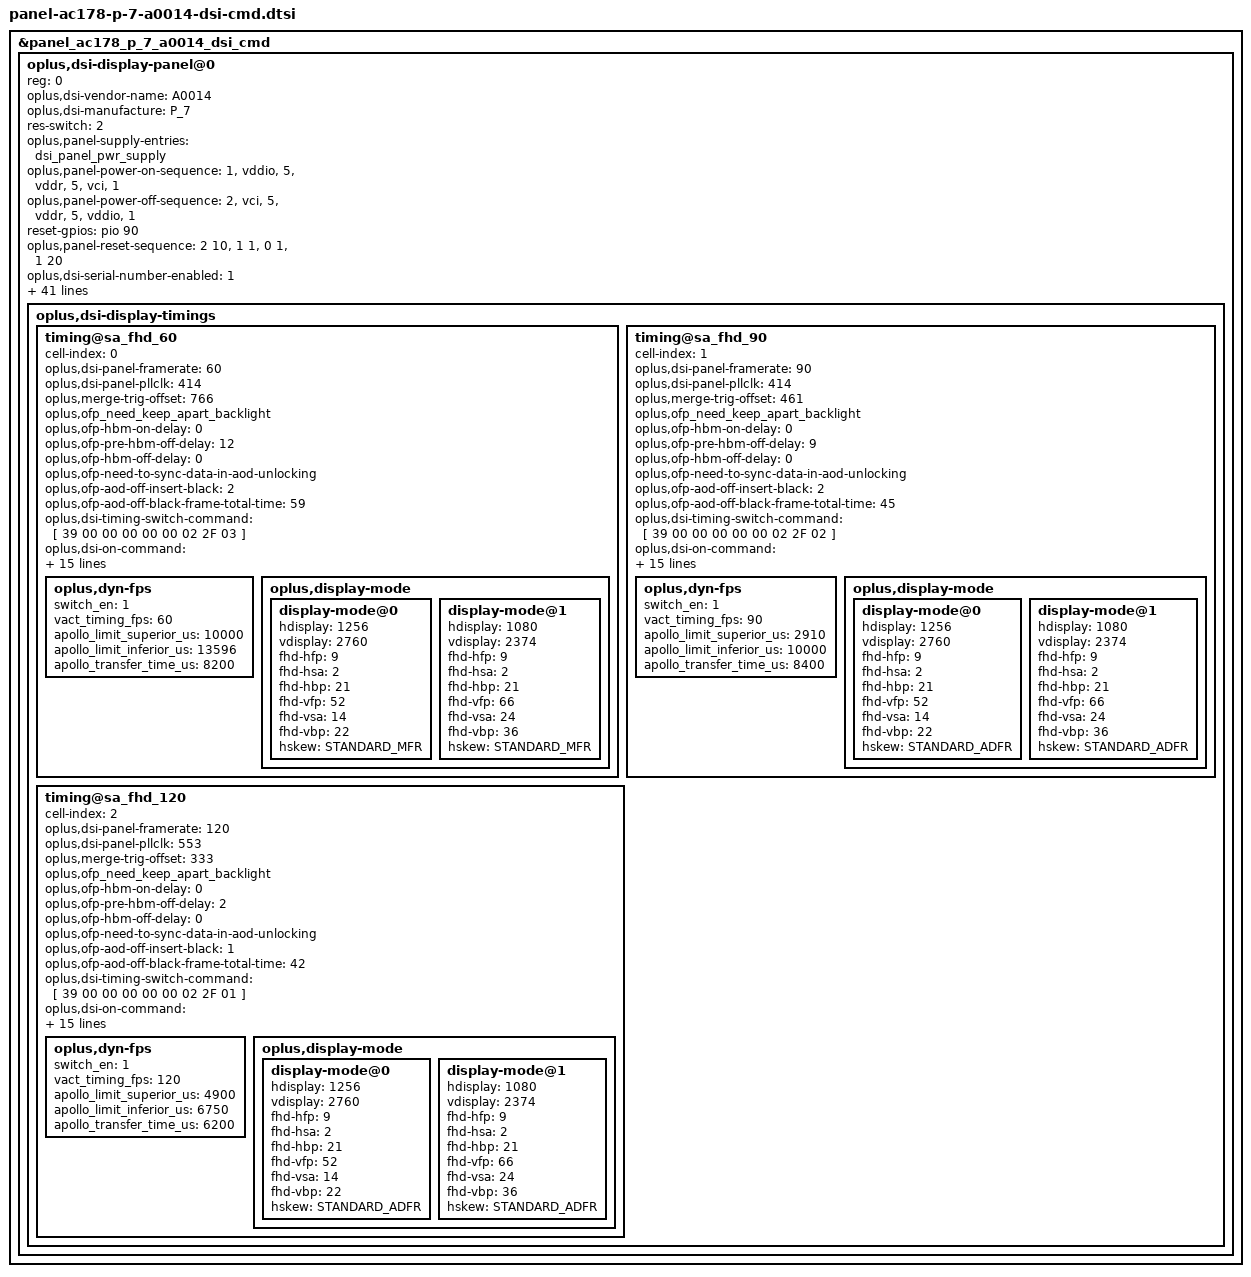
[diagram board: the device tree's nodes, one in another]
&panel_ac178_p_7_a0014_dsi_cmd {
	oplus,dsi-display-panel@0 {
		reg = <0>;
		oplus,dsi-vendor-name = "A0014";
		oplus,dsi-manufacture = "P_7";
		/* round corner */
		#include "panel-ac178-p-7-a0014-dsi-cmd-round-corner.dtsi"
		oplus,dsi-display-timings {
			timing@sa_fhd_60 {
				cell-index = <0>;
				oplus,dsi-panel-framerate = <60>;
				oplus,dsi-panel-pllclk = <414>;
				oplus,merge-trig-offset = <766>;
				/* OPLUS_FEATURE_DISPLAY_ONSCREENFINGERPRINT */
				oplus,ofp_need_keep_apart_backlight;
				oplus,ofp-hbm-on-delay = <0>;
				oplus,ofp-pre-hbm-off-delay = <12>;
				oplus,ofp-hbm-off-delay = <0>;
				oplus,ofp-need-to-sync-data-in-aod-unlocking;
				oplus,ofp-aod-off-insert-black = <2>;
				oplus,ofp-aod-off-black-frame-total-time = <59>;
				#include "panel-ac178-p-7-a0014-dsi-cmd-common.dtsi"
				oplus,dsi-timing-switch-command = [
					39 00 00 00 00 00 02 2F 03
				];
				oplus,dsi-on-command = [
					39 00 00 00 00 00 05 FF AA 55 A5 80
					39 00 00 00 00 00 02 6F 31
					39 00 00 00 00 00 03 F8 01 BD
					39 00 00 00 00 00 05 FF AA 55 A5 80
					39 00 00 00 00 00 02 6F 15
					39 00 00 00 00 00 03 F8 01 8C
					39 00 00 00 00 00 02 5A 01
					39 00 00 00 00 00 06 F0 55 AA 52 08 07
					39 00 00 00 00 00 02 C1 00
					39 00 00 00 00 00 02 C2 00
					39 00 00 00 00 00 02 C3 00
					39 00 00 00 00 00 02 C4 00
					39 00 00 00 00 00 02 C5 00
					39 00 00 00 00 00 02 C6 00
					39 00 00 00 00 00 02 D1 00
					39 00 00 00 00 00 05 FF AA 55 A5 80
					39 00 00 00 00 00 02 6F 0A
					39 00 00 00 00 00 06 F6 70 70 70 70 70
					39 00 00 00 00 00 05 FF AA 55 A5 81
					39 00 00 00 00 00 02 6F 0D
					39 00 00 00 00 00 02 FB 80
					39 00 00 00 00 00 06 F0 55 AA 52 08 01
					39 00 00 00 00 00 02 E5 00
					39 00 00 00 00 00 05 FF AA 55 A5 81
					39 00 00 00 00 00 02 6F 0C
					39 00 00 00 00 00 02 FD 08
					39 00 00 00 00 00 02 6F 02
					39 00 00 00 00 00 02 F9 84
					39 00 00 00 00 00 02 6F 10
					39 00 00 00 00 00 02 FB 40
					39 00 00 00 00 00 02 6F 0B
					39 00 00 00 00 00 02 FD 00
					39 00 00 00 00 00 05 FF AA 55 A5 80
					39 00 00 00 00 00 02 6F 48
					39 00 00 00 00 00 02 F2 00
					39 00 00 00 00 00 02 6F 16
					39 00 00 00 00 00 03 F4 02 74
					39 00 00 00 00 00 02 6F 42
					39 00 00 00 00 00 02 F4 00
					39 00 00 00 00 00 02 6F 49
					39 00 00 00 00 00 02 F2 10
					39 00 00 00 00 00 05 FF AA 55 A5 81
					39 00 00 00 00 00 02 6F 05
					39 00 00 00 00 00 03 FE 3C 3C
					39 00 00 00 00 00 05 FF AA 55 A5 82
					39 00 00 00 00 00 02 6F 09
					39 00 00 00 00 00 02 F2 FF
					39 00 00 00 00 00 05 FF AA 55 A5 80
					39 00 00 00 00 00 02 6F 04
					39 00 00 00 00 00 02 F2 3C
					39 00 00 00 00 00 02 17 30
					39 00 00 00 00 00 02 2F 03
					39 00 00 00 00 00 03 5F 00 00
					39 00 00 00 00 00 02 35 00
					39 00 00 00 00 00 02 53 20
					39 00 00 00 00 00 05 2A 00 00 04 E7
					39 00 00 00 00 00 05 2B 00 00 0A C7
					39 00 00 00 00 00 06 F0 55 AA 52 08 02
					39 00 00 00 00 00 02 C1 02
					39 00 00 00 00 00 05 C2 19 00 91 00
					39 00 00 00 00 00 06 F0 55 AA 52 08 03
					39 00 00 00 00 00 02 6F 08
					39 00 00 00 00 00 02 DE 00
					39 00 00 00 00 00 02 6F 09
					39 00 00 00 00 00 07 DE 10 34 25 30 14 25
					39 00 00 00 00 00 06 F0 55 AA 52 08 07
					39 00 00 00 00 00 02 B0 44
					39 00 00 00 00 00 07 B1 60 60 00 60 60 00
					39 00 00 00 00 00 03 90 03 43
					39 00 00 00 00 00 02 03 00
					39 00 00 00 00 00 13 91 A0 F0 00 0C D1 00 01 D2 00 57 00 34 09 75 29 25 11 50
					39 00 00 00 00 00 13 93 AB A8 00 0C C2 00 02 3B 01 35 00 08 08 BB 07 44 10 F0
					39 00 00 00 00 00 02 26 00
					39 00 00 00 00 00 06 F0 55 AA 52 08 01
					39 00 00 00 00 00 02 DD 4F
					39 00 00 00 00 00 03 81 01 19
					39 00 00 00 00 00 06 F0 55 AA 52 08 00
					39 00 00 00 00 00 02 6F 03
					39 00 00 00 00 00 02 B5 65
					39 00 00 00 00 00 02 6F 08
					39 00 00 00 00 00 02 D5 04
					39 00 00 00 00 00 02 6F 19
					39 00 00 00 00 00 02 D5 0E // DVDD 1.05V
					39 00 00 00 00 00 02 6F 4D
					39 00 00 00 00 00 02 D5 01
					39 00 00 00 00 00 06 F0 55 AA 52 08 01
					39 00 00 00 00 00 02 CE 00
					39 00 00 00 00 00 06 F0 55 AA 52 08 01
					39 00 00 00 00 00 02 6F 0E
					39 00 00 00 00 00 02 D2 00
					39 00 00 00 00 00 02 6F 03
					39 00 00 00 00 00 04 C5 00 23 23 // DVDD STRONG 1.01
					39 00 00 00 00 00 06 F0 55 AA 52 08 00
					39 00 00 00 00 00 02 C0 56
					39 00 00 00 00 00 0A 88 01 02 74 09 B4 00 00 00 00
					39 00 00 00 00 00 06 F0 55 AA 52 08 00
					39 00 00 00 00 00 02 6F 13
					39 00 00 00 00 00 19 DF 00 64 00 64 00 00 00 00 00 00 00 00 00 C7 00 C7 00 00 00 00 00 00 00 00
					39 00 00 00 00 00 06 F0 55 AA 52 08 07
					39 00 00 00 00 00 16 C9 21 00 26 49 26 49 00 00 3F E2 63 8A 3F E2 63 8A 00 05 B9 C0 D1
					39 00 00 00 00 00 02 6F 15
					39 00 00 00 00 00 11 C9 1C 00 00 63 00 00 63 33 F0 9D 9D 26 49 00 00 00
					39 00 00 00 00 00 16 CA 2D 00 26 49 26 49 00 00 3F E2 63 8A 00 00 00 00 00 00 00 00 00
					39 00 00 00 00 00 02 6F 15
					39 00 00 00 00 00 11 CA 46 00 00 63 00 64 C7 33 C0 9D 63 00 00 00 00 00
					39 00 00 00 00 00 16 CB 2B 00 26 49 26 49 00 00 00 00 00 00 00 00 00 00 7F FA 46 3F 2F
					39 00 00 00 00 00 02 6F 15
					39 00 00 00 00 00 11 CB 46 00 64 C7 00 64 C7 33 0F 63 63 D9 B7 00 00 00
					39 00 00 00 00 00 16 CC 27 00 26 49 26 49 00 00 00 00 00 00 3F E2 63 8A 00 00 00 00 00
					39 00 00 00 00 00 02 6F 15
					39 00 00 00 00 00 11 CC 1C 00 64 C7 00 00 63 33 30 63 9D 00 00 00 00 00
					39 00 00 00 00 00 06 F0 55 AA 52 08 00
					39 00 00 00 00 00 03 DF 01 44
					39 00 00 00 00 00 06 F0 55 AA 52 08 08
					39 00 00 00 00 00 02 6F 30
					39 00 00 00 00 00 15 B2 00 00 3B 45 21 C4 25 E4 2A C4 2F 64 3A 44 24 C3 30 C3 3A 93
					39 00 00 00 00 00 02 6F 44
					39 00 00 00 00 00 15 B2 24 02 2B C2 35 52 1F 71 24 D1 2A E1 31 81 35 81 20 90 24 C0
					39 00 00 00 00 00 02 6F 58
					39 00 00 00 00 00 0B B2 29 00 2D 50 00 1F 00 1F 00 1F
					39 00 00 00 00 00 06 F0 55 AA 52 08 00
					39 00 00 00 00 00 02 C3 04
					39 00 00 00 00 00 06 F0 55 AA 52 08 08
					39 00 00 00 00 00 07 B0 11 05 39 1D 20 20
					39 00 00 00 00 00 02 6F 07
					39 00 00 00 00 00 08 B0 21 D3 6C 32 ED 6E F3
					39 00 00 00 00 00 02 6F 0E
					39 00 00 00 00 00 08 B0 FF FF 31 DE BC E3 BC
					39 00 00 00 00 00 02 6F 15
					39 00 00 00 00 00 08 B0 E1 FF FF FF 05 AD 16
					39 00 00 00 00 00 02 6F 1C
					39 00 00 00 00 00 05 B0 FE 8A 00 17
					39 00 00 00 78 00 01 11
					39 00 00 00 00 00 01 29
				];
				oplus,dsi-aod-off-command = [
					39 00 00 40 00 00 02 38 00
					39 00 00 00 00 00 03 51 00 00
				];
				oplus,dsi-hbm-on-command = [
					39 00 00 00 00 00 03 51 0E 7A
				];
				oplus,dsi-hbm-off-command = [
					39 00 00 00 00 00 03 51 0D BB
				];

				oplus,dsi-timing-switch-command-state = "dsi_hs_mode";
				oplus,dsi-on-command-state = "dsi_lp_mode";
				oplus,dsi-aod-off-command-state = "dsi_ls_mode";
				oplus,dsi-hbm-on-command-state = "dsi_hs_mode";
				oplus,dsi-hbm-off-command-state = "dsi_hs_mode";
				oplus,dsc-params-entries = <&dsc_params>;
				oplus,spr-params-entries = <&spr_params>;
				oplus,dyn-fps {
					switch_en = <1>;
					vact_timing_fps = <60>;
					apollo_limit_superior_us = <10000>;
					apollo_limit_inferior_us = <13596>;
					apollo_transfer_time_us = <8200>;
				};
				oplus,display-mode {
					display-mode@0 {
						hdisplay = <1256>;
						vdisplay = <2760>;
						fhd-hfp = <9>;
						fhd-hsa = <2>;
						fhd-hbp = <21>;
						fhd-vfp = <52>;
						fhd-vsa = <14>;
						fhd-vbp = <22>;
						hskew = <STANDARD_MFR>;
					};
					display-mode@1 {
						hdisplay = <1080>;
						vdisplay = <2374>;
						fhd-hfp = <9>;
						fhd-hsa = <2>;
						fhd-hbp = <21>;
						fhd-vfp = <66>;
						fhd-vsa = <24>;
						fhd-vbp = <36>;
						hskew = <STANDARD_MFR>;
					};
				};
			};
			timing@sa_fhd_90 {
				cell-index = <1>;
				oplus,dsi-panel-framerate = <90>;
				oplus,dsi-panel-pllclk = <414>;
				oplus,merge-trig-offset = <461>;
				/* OPLUS_FEATURE_DISPLAY_ONSCREENFINGERPRINT */
				oplus,ofp_need_keep_apart_backlight;
				oplus,ofp-hbm-on-delay = <0>;
				oplus,ofp-pre-hbm-off-delay = <9>;
				oplus,ofp-hbm-off-delay = <0>;
				oplus,ofp-need-to-sync-data-in-aod-unlocking;
				oplus,ofp-aod-off-insert-black = <2>;
				oplus,ofp-aod-off-black-frame-total-time = <45>;
				#include "panel-ac178-p-7-a0014-dsi-cmd-common.dtsi"
				oplus,dsi-timing-switch-command = [
					39 00 00 00 00 00 02 2F 02
				];
				oplus,dsi-on-command = [
					39 00 00 00 00 00 05 FF AA 55 A5 80
					39 00 00 00 00 00 02 6F 31
					39 00 00 00 00 00 03 F8 01 BD
					39 00 00 00 00 00 05 FF AA 55 A5 80
					39 00 00 00 00 00 02 6F 15
					39 00 00 00 00 00 03 F8 01 8C
					39 00 00 00 00 00 02 5A 01
					39 00 00 00 00 00 06 F0 55 AA 52 08 07
					39 00 00 00 00 00 02 C1 00
					39 00 00 00 00 00 02 C2 00
					39 00 00 00 00 00 02 C3 00
					39 00 00 00 00 00 02 C4 00
					39 00 00 00 00 00 02 C5 00
					39 00 00 00 00 00 02 C6 00
					39 00 00 00 00 00 02 D1 00
					39 00 00 00 00 00 05 FF AA 55 A5 80
					39 00 00 00 00 00 02 6F 0A
					39 00 00 00 00 00 06 F6 70 70 70 70 70
					39 00 00 00 00 00 05 FF AA 55 A5 81
					39 00 00 00 00 00 02 6F 0D
					39 00 00 00 00 00 02 FB 80
					39 00 00 00 00 00 06 F0 55 AA 52 08 01
					39 00 00 00 00 00 02 E5 00
					39 00 00 00 00 00 05 FF AA 55 A5 81
					39 00 00 00 00 00 02 6F 0C
					39 00 00 00 00 00 02 FD 08
					39 00 00 00 00 00 02 6F 02
					39 00 00 00 00 00 02 F9 84
					39 00 00 00 00 00 02 6F 10
					39 00 00 00 00 00 02 FB 40
					39 00 00 00 00 00 02 6F 0B
					39 00 00 00 00 00 02 FD 00
					39 00 00 00 00 00 05 FF AA 55 A5 80
					39 00 00 00 00 00 02 6F 48
					39 00 00 00 00 00 02 F2 00
					39 00 00 00 00 00 02 6F 16
					39 00 00 00 00 00 03 F4 02 74
					39 00 00 00 00 00 02 6F 42
					39 00 00 00 00 00 02 F4 00
					39 00 00 00 00 00 02 6F 49
					39 00 00 00 00 00 02 F2 10
					39 00 00 00 00 00 05 FF AA 55 A5 81
					39 00 00 00 00 00 02 6F 05
					39 00 00 00 00 00 03 FE 3C 3C
					39 00 00 00 00 00 05 FF AA 55 A5 82
					39 00 00 00 00 00 02 6F 09
					39 00 00 00 00 00 02 F2 FF
					39 00 00 00 00 00 05 FF AA 55 A5 80
					39 00 00 00 00 00 02 6F 04
					39 00 00 00 00 00 02 F2 3C
					39 00 00 00 00 00 02 17 30
					39 00 00 00 00 00 02 2F 02
					39 00 00 00 00 00 03 5F 00 00
					39 00 00 00 00 00 02 35 00
					39 00 00 00 00 00 02 53 20
					39 00 00 00 00 00 05 2A 00 00 04 E7
					39 00 00 00 00 00 05 2B 00 00 0A C7
					39 00 00 00 00 00 06 F0 55 AA 52 08 02
					39 00 00 00 00 00 02 C1 02
					39 00 00 00 00 00 05 C2 19 00 91 00
					39 00 00 00 00 00 06 F0 55 AA 52 08 03
					39 00 00 00 00 00 02 6F 08
					39 00 00 00 00 00 02 DE 00
					39 00 00 00 00 00 02 6F 09
					39 00 00 00 00 00 07 DE 10 34 25 30 14 25
					39 00 00 00 00 00 06 F0 55 AA 52 08 07
					39 00 00 00 00 00 02 B0 44
					39 00 00 00 00 00 07 B1 60 60 00 60 60 00
					39 00 00 00 00 00 03 90 03 43
					39 00 00 00 00 00 02 03 00
					39 00 00 00 00 00 13 91 A0 F0 00 0C D1 00 01 D2 00 57 00 34 09 75 29 25 11 50
					39 00 00 00 00 00 13 93 AB A8 00 0C C2 00 02 3B 01 35 00 08 08 BB 07 44 10 F0
					39 00 00 00 00 00 02 26 00
					39 00 00 00 00 00 06 F0 55 AA 52 08 01
					39 00 00 00 00 00 02 DD 4F
					39 00 00 00 00 00 03 81 01 19
					39 00 00 00 00 00 06 F0 55 AA 52 08 00
					39 00 00 00 00 00 02 6F 03
					39 00 00 00 00 00 02 B5 65
					39 00 00 00 00 00 02 6F 08
					39 00 00 00 00 00 02 D5 04
					39 00 00 00 00 00 02 6F 19
					39 00 00 00 00 00 02 D5 0E // DVDD 1.05V
					39 00 00 00 00 00 02 6F 4D
					39 00 00 00 00 00 02 D5 01
					39 00 00 00 00 00 06 F0 55 AA 52 08 01
					39 00 00 00 00 00 02 CE 00
					39 00 00 00 00 00 06 F0 55 AA 52 08 01
					39 00 00 00 00 00 02 6F 0E
					39 00 00 00 00 00 02 D2 00
					39 00 00 00 00 00 02 6F 03
					39 00 00 00 00 00 04 C5 00 23 23 // DVDD STRONG 1.01
					39 00 00 00 00 00 06 F0 55 AA 52 08 00
					39 00 00 00 00 00 02 C0 56
					39 00 00 00 00 00 0A 88 01 02 74 09 B4 00 00 00 00
					39 00 00 00 00 00 06 F0 55 AA 52 08 00
					39 00 00 00 00 00 02 6F 13
					39 00 00 00 00 00 19 DF 00 64 00 64 00 00 00 00 00 00 00 00 00 C7 00 C7 00 00 00 00 00 00 00 00
					39 00 00 00 00 00 06 F0 55 AA 52 08 07
					39 00 00 00 00 00 16 C9 21 00 26 49 26 49 00 00 3F E2 63 8A 3F E2 63 8A 00 05 B9 C0 D1
					39 00 00 00 00 00 02 6F 15
					39 00 00 00 00 00 11 C9 1C 00 00 63 00 00 63 33 F0 9D 9D 26 49 00 00 00
					39 00 00 00 00 00 16 CA 2D 00 26 49 26 49 00 00 3F E2 63 8A 00 00 00 00 00 00 00 00 00
					39 00 00 00 00 00 02 6F 15
					39 00 00 00 00 00 11 CA 46 00 00 63 00 64 C7 33 C0 9D 63 00 00 00 00 00
					39 00 00 00 00 00 16 CB 2B 00 26 49 26 49 00 00 00 00 00 00 00 00 00 00 7F FA 46 3F 2F
					39 00 00 00 00 00 02 6F 15
					39 00 00 00 00 00 11 CB 46 00 64 C7 00 64 C7 33 0F 63 63 D9 B7 00 00 00
					39 00 00 00 00 00 16 CC 27 00 26 49 26 49 00 00 00 00 00 00 3F E2 63 8A 00 00 00 00 00
					39 00 00 00 00 00 02 6F 15
					39 00 00 00 00 00 11 CC 1C 00 64 C7 00 00 63 33 30 63 9D 00 00 00 00 00
					39 00 00 00 00 00 06 F0 55 AA 52 08 00
					39 00 00 00 00 00 03 DF 01 44
					39 00 00 00 00 00 06 F0 55 AA 52 08 08
					39 00 00 00 00 00 02 6F 30
					39 00 00 00 00 00 15 B2 00 00 3B 45 21 C4 25 E4 2A C4 2F 64 3A 44 24 C3 30 C3 3A 93
					39 00 00 00 00 00 02 6F 44
					39 00 00 00 00 00 15 B2 24 02 2B C2 35 52 1F 71 24 D1 2A E1 31 81 35 81 20 90 24 C0
					39 00 00 00 00 00 02 6F 58
					39 00 00 00 00 00 0B B2 29 00 2D 50 00 1F 00 1F 00 1F
					39 00 00 00 00 00 06 F0 55 AA 52 08 00
					39 00 00 00 00 00 02 C3 04
					39 00 00 00 00 00 06 F0 55 AA 52 08 08
					39 00 00 00 00 00 07 B0 11 05 39 1D 20 20
					39 00 00 00 00 00 02 6F 07
					39 00 00 00 00 00 08 B0 21 D3 6C 32 ED 6E F3
					39 00 00 00 00 00 02 6F 0E
					39 00 00 00 00 00 08 B0 FF FF 31 DE BC E3 BC
					39 00 00 00 00 00 02 6F 15
					39 00 00 00 00 00 08 B0 E1 FF FF FF 05 AD 16
					39 00 00 00 00 00 02 6F 1C
					39 00 00 00 00 00 05 B0 FE 8A 00 17
					39 00 00 00 78 00 01 11
					39 00 00 00 00 00 01 29
				];
				oplus,dsi-aod-off-command = [
					39 00 00 40 00 00 02 38 00
					39 00 00 00 00 00 03 51 00 00
				];
				oplus,dsi-hbm-on-command = [
					39 00 00 00 00 00 03 51 0E 7A
				];
				oplus,dsi-hbm-off-command = [
					39 00 00 00 00 00 03 51 0D BB
				];

				oplus,dsi-timing-switch-command-state = "dsi_hs_mode";
				oplus,dsi-on-command-state = "dsi_lp_mode";
				oplus,dsi-aod-off-command-state = "dsi_ls_mode";
				oplus,dsi-hbm-on-command-state = "dsi_hs_mode";
				oplus,dsi-hbm-off-command-state = "dsi_hs_mode";
				oplus,dsc-params-entries = <&dsc_params>;
				oplus,spr-params-entries = <&spr_params>;
				oplus,dyn-fps {
					switch_en = <1>;
					vact_timing_fps = <90>;
					apollo_limit_superior_us = <2910>;
					apollo_limit_inferior_us = <10000>;
					apollo_transfer_time_us = <8400>;
				};
				oplus,display-mode {
					display-mode@0 {
						hdisplay = <1256>;
						vdisplay = <2760>;
						fhd-hfp = <9>;
						fhd-hsa = <2>;
						fhd-hbp = <21>;
						fhd-vfp = <52>;
						fhd-vsa = <14>;
						fhd-vbp = <22>;
						hskew = <STANDARD_ADFR>;
					};
					display-mode@1 {
						hdisplay = <1080>;
						vdisplay = <2374>;
						fhd-hfp = <9>;
						fhd-hsa = <2>;
						fhd-hbp = <21>;
						fhd-vfp = <66>;
						fhd-vsa = <24>;
						fhd-vbp = <36>;
						hskew = <STANDARD_ADFR>;
					};
				};
			};
			timing@sa_fhd_120 {
				cell-index = <2>;
				oplus,dsi-panel-framerate = <120>;
				oplus,dsi-panel-pllclk = <553>;
				oplus,merge-trig-offset = <333>;
				/* OPLUS_FEATURE_DISPLAY_ONSCREENFINGERPRINT */
				oplus,ofp_need_keep_apart_backlight;
				oplus,ofp-hbm-on-delay = <0>;
				oplus,ofp-pre-hbm-off-delay = <2>;
				oplus,ofp-hbm-off-delay = <0>;
				oplus,ofp-need-to-sync-data-in-aod-unlocking;
				oplus,ofp-aod-off-insert-black = <1>;
				oplus,ofp-aod-off-black-frame-total-time = <42>;
				#include "panel-ac178-p-7-a0014-dsi-cmd-common.dtsi"
				oplus,dsi-timing-switch-command = [
					39 00 00 00 00 00 02 2F 01
				];
				oplus,dsi-on-command = [
					39 00 00 00 00 00 05 FF AA 55 A5 80
					39 00 00 00 00 00 02 6F 31
					39 00 00 00 00 00 03 F8 01 BD
					39 00 00 00 00 00 05 FF AA 55 A5 80
					39 00 00 00 00 00 02 6F 15
					39 00 00 00 00 00 03 F8 01 8C
					39 00 00 00 00 00 02 5A 01
					39 00 00 00 00 00 06 F0 55 AA 52 08 07
					39 00 00 00 00 00 02 C1 00
					39 00 00 00 00 00 02 C2 00
					39 00 00 00 00 00 02 C3 00
					39 00 00 00 00 00 02 C4 00
					39 00 00 00 00 00 02 C5 00
					39 00 00 00 00 00 02 C6 00
					39 00 00 00 00 00 02 D1 00
					39 00 00 00 00 00 05 FF AA 55 A5 80
					39 00 00 00 00 00 02 6F 0A
					39 00 00 00 00 00 06 F6 70 70 70 70 70
					39 00 00 00 00 00 05 FF AA 55 A5 81
					39 00 00 00 00 00 02 6F 0D
					39 00 00 00 00 00 02 FB 80
					39 00 00 00 00 00 06 F0 55 AA 52 08 01
					39 00 00 00 00 00 02 E5 00
					39 00 00 00 00 00 05 FF AA 55 A5 81
					39 00 00 00 00 00 02 6F 0C
					39 00 00 00 00 00 02 FD 08
					39 00 00 00 00 00 02 6F 02
					39 00 00 00 00 00 02 F9 84
					39 00 00 00 00 00 02 6F 10
					39 00 00 00 00 00 02 FB 40
					39 00 00 00 00 00 02 6F 0B
					39 00 00 00 00 00 02 FD 00
					39 00 00 00 00 00 05 FF AA 55 A5 80
					39 00 00 00 00 00 02 6F 48
					39 00 00 00 00 00 02 F2 00
					39 00 00 00 00 00 02 6F 16
					39 00 00 00 00 00 03 F4 02 74
					39 00 00 00 00 00 02 6F 42
					39 00 00 00 00 00 02 F4 00
					39 00 00 00 00 00 02 6F 49
					39 00 00 00 00 00 02 F2 10
					39 00 00 00 00 00 05 FF AA 55 A5 81
					39 00 00 00 00 00 02 6F 05
					39 00 00 00 00 00 03 FE 3C 3C
					39 00 00 00 00 00 05 FF AA 55 A5 82
					39 00 00 00 00 00 02 6F 09
					39 00 00 00 00 00 02 F2 FF
					39 00 00 00 00 00 05 FF AA 55 A5 80
					39 00 00 00 00 00 02 6F 04
					39 00 00 00 00 00 02 F2 3C
					39 00 00 00 00 00 02 17 30
					39 00 00 00 00 00 02 2F 01
					39 00 00 00 00 00 03 5F 00 00
					39 00 00 00 00 00 02 35 00
					39 00 00 00 00 00 02 53 20
					39 00 00 00 00 00 05 2A 00 00 04 E7
					39 00 00 00 00 00 05 2B 00 00 0A C7
					39 00 00 00 00 00 06 F0 55 AA 52 08 02
					39 00 00 00 00 00 02 C1 02
					39 00 00 00 00 00 05 C2 19 00 91 00
					39 00 00 00 00 00 06 F0 55 AA 52 08 03
					39 00 00 00 00 00 02 6F 08
					39 00 00 00 00 00 02 DE 00
					39 00 00 00 00 00 02 6F 09
					39 00 00 00 00 00 07 DE 10 34 25 30 14 25
					39 00 00 00 00 00 06 F0 55 AA 52 08 07
					39 00 00 00 00 00 02 B0 44
					39 00 00 00 00 00 07 B1 60 60 00 60 60 00
					39 00 00 00 00 00 03 90 03 43
					39 00 00 00 00 00 02 03 00
					39 00 00 00 00 00 13 91 A0 F0 00 0C D1 00 01 D2 00 57 00 34 09 75 29 25 11 50
					39 00 00 00 00 00 13 93 AB A8 00 0C C2 00 02 3B 01 35 00 08 08 BB 07 44 10 F0
					39 00 00 00 00 00 02 26 00
					39 00 00 00 00 00 06 F0 55 AA 52 08 01
					39 00 00 00 00 00 02 DD 4F
					39 00 00 00 00 00 03 81 01 19
					39 00 00 00 00 00 06 F0 55 AA 52 08 00
					39 00 00 00 00 00 02 6F 03
					39 00 00 00 00 00 02 B5 65
					39 00 00 00 00 00 02 6F 08
					39 00 00 00 00 00 02 D5 04
					39 00 00 00 00 00 02 6F 19
					39 00 00 00 00 00 02 D5 0E // DVDD 1.05V
					39 00 00 00 00 00 02 6F 4D
					39 00 00 00 00 00 02 D5 01
					39 00 00 00 00 00 06 F0 55 AA 52 08 01
					39 00 00 00 00 00 02 CE 00
					39 00 00 00 00 00 06 F0 55 AA 52 08 01
					39 00 00 00 00 00 02 6F 0E
					39 00 00 00 00 00 02 D2 00
					39 00 00 00 00 00 02 6F 03
					39 00 00 00 00 00 04 C5 00 23 23 // DVDD STRONG 1.01
					39 00 00 00 00 00 06 F0 55 AA 52 08 00
					39 00 00 00 00 00 02 C0 56
					39 00 00 00 00 00 0A 88 01 02 74 09 B4 00 00 00 00
					39 00 00 00 00 00 06 F0 55 AA 52 08 00
					39 00 00 00 00 00 02 6F 13
					39 00 00 00 00 00 19 DF 00 64 00 64 00 00 00 00 00 00 00 00 00 C7 00 C7 00 00 00 00 00 00 00 00
					39 00 00 00 00 00 06 F0 55 AA 52 08 07
					39 00 00 00 00 00 16 C9 21 00 26 49 26 49 00 00 3F E2 63 8A 3F E2 63 8A 00 05 B9 C0 D1
					39 00 00 00 00 00 02 6F 15
					39 00 00 00 00 00 11 C9 1C 00 00 63 00 00 63 33 F0 9D 9D 26 49 00 00 00
					39 00 00 00 00 00 16 CA 2D 00 26 49 26 49 00 00 3F E2 63 8A 00 00 00 00 00 00 00 00 00
					39 00 00 00 00 00 02 6F 15
					39 00 00 00 00 00 11 CA 46 00 00 63 00 64 C7 33 C0 9D 63 00 00 00 00 00
					39 00 00 00 00 00 16 CB 2B 00 26 49 26 49 00 00 00 00 00 00 00 00 00 00 7F FA 46 3F 2F
					39 00 00 00 00 00 02 6F 15
					39 00 00 00 00 00 11 CB 46 00 64 C7 00 64 C7 33 0F 63 63 D9 B7 00 00 00
					39 00 00 00 00 00 16 CC 27 00 26 49 26 49 00 00 00 00 00 00 3F E2 63 8A 00 00 00 00 00
					39 00 00 00 00 00 02 6F 15
					39 00 00 00 00 00 11 CC 1C 00 64 C7 00 00 63 33 30 63 9D 00 00 00 00 00
					39 00 00 00 00 00 06 F0 55 AA 52 08 00
					39 00 00 00 00 00 03 DF 01 44
					39 00 00 00 00 00 06 F0 55 AA 52 08 08
					39 00 00 00 00 00 02 6F 30
					39 00 00 00 00 00 15 B2 00 00 3B 45 21 C4 25 E4 2A C4 2F 64 3A 44 24 C3 30 C3 3A 93
					39 00 00 00 00 00 02 6F 44
					39 00 00 00 00 00 15 B2 24 02 2B C2 35 52 1F 71 24 D1 2A E1 31 81 35 81 20 90 24 C0
					39 00 00 00 00 00 02 6F 58
					39 00 00 00 00 00 0B B2 29 00 2D 50 00 1F 00 1F 00 1F
					39 00 00 00 00 00 06 F0 55 AA 52 08 00
					39 00 00 00 00 00 02 C3 04
					39 00 00 00 00 00 06 F0 55 AA 52 08 08
					39 00 00 00 00 00 07 B0 11 05 39 1D 20 20
					39 00 00 00 00 00 02 6F 07
					39 00 00 00 00 00 08 B0 21 D3 6C 32 ED 6E F3
					39 00 00 00 00 00 02 6F 0E
					39 00 00 00 00 00 08 B0 FF FF 31 DE BC E3 BC
					39 00 00 00 00 00 02 6F 15
					39 00 00 00 00 00 08 B0 E1 FF FF FF 05 AD 16
					39 00 00 00 00 00 02 6F 1C
					39 00 00 00 00 00 05 B0 FE 8A 00 17
					39 00 00 00 78 00 01 11
					39 00 00 00 00 00 01 29
				];
				oplus,dsi-aod-off-command = [
					39 00 00 40 00 00 02 38 00
					39 00 00 00 00 00 03 51 00 00
				];
				oplus,dsi-hbm-on-command = [
					39 00 00 00 00 00 03 51 0E 7A
				];
				oplus,dsi-hbm-off-command = [
					39 00 00 00 00 00 03 51 0D BB
				];

				oplus,dsi-timing-switch-command-state = "dsi_hs_mode";
				oplus,dsi-on-command-state = "dsi_lp_mode";
				oplus,dsi-aod-off-command-state = "dsi_ls_mode";
				oplus,dsi-hbm-on-command-state = "dsi_hs_mode";
				oplus,dsi-hbm-off-command-state = "dsi_hs_mode";
				oplus,dsc-params-entries = <&dsc_params>;
				oplus,spr-params-entries = <&spr_params>;
				oplus,dyn-fps {
					switch_en = <1>;
					vact_timing_fps = <120>;
					apollo_limit_superior_us = <4900>;
					apollo_limit_inferior_us = <6750>;
					apollo_transfer_time_us = <6200>;
				};
				oplus,display-mode {
					display-mode@0 {
						hdisplay = <1256>;
						vdisplay = <2760>;
						fhd-hfp = <9>;
						fhd-hsa = <2>;
						fhd-hbp = <21>;
						fhd-vfp = <52>;
						fhd-vsa = <14>;
						fhd-vbp = <22>;
						hskew = <STANDARD_ADFR>;
					};
					display-mode@1 {
						hdisplay = <1080>;
						vdisplay = <2374>;
						fhd-hfp = <9>;
						fhd-hsa = <2>;
						fhd-hbp = <21>;
						fhd-vfp = <66>;
						fhd-vsa = <24>;
						fhd-vbp = <36>;
						hskew = <STANDARD_ADFR>;
					};
				};
			};
		};
	};
};

&panel_ac178_p_7_a0014_dsi_cmd {
	oplus,dsi-display-panel@0 {
		res-switch = <2>;
		/* Hardware config */
		oplus,panel-supply-entries = <&dsi_panel_pwr_supply>;
		oplus,panel-power-on-sequence = "1", "vddio", "5", "vddr", "5", "vci", "1";
		oplus,panel-power-off-sequence = "2", "vci", "5", "vddr", "5", "vddio", "1";
		reset-gpios = <&pio 90 0>;
		oplus,panel-reset-sequence = <2 10>, <1 1>, <0 1>, <1 20>;
		/* Panel config */
		oplus,dsi-serial-number-enabled = <1>;
		oplus,dsi-serial-number-index = <0>;
		oplus,dsi-serial-number-reg = <0xA3>;
		oplus,dsi-serial-number-read-count = <6>;
		oplus,dsi-serial-number-year-offset = <10>;
		oplus,mode-switch-h2l-delay;
		oplus,keep_ulps = <1>;
		oplus,demura-dbv-enable;
		oplus,emduty-dbv-cfg = <699 772 843 900 929 1153>;
		oplus,demura-dbv-cfg = <1153 4094>;
		/* PWM config */
		oplus,pwm-turbo-support = <0>; /* 0 not support, 1 with switch, 2 Global high frequency pwm without switch */
		oplus,pwm-switch-backlight-threshold = <0x481>;
		/* ADFR config */
		oplus-adfr-config = <0>;
		/* OFP config */
		oplus,ofp-fp-type = <0x10>;
		oplus,ofp-longrui-aod-config = <0x02>;
		/* ext_params */
		oplus,panel-type = <2>;
		oplus,lane-swap-en = <0>;
		oplus,lane-swap = <
			MIPITX_PHY_LANE_0 MIPITX_PHY_LANE_1 MIPITX_PHY_LANE_3 MIPITX_PHY_LANE_2 MIPITX_PHY_LANE_CK MIPITX_PHY_LANE_0
			MIPITX_PHY_LANE_0 MIPITX_PHY_LANE_1 MIPITX_PHY_LANE_3 MIPITX_PHY_LANE_2 MIPITX_PHY_LANE_CK MIPITX_PHY_LANE_0
		>;
		oplus,lcm-color-mode = <MTK_DRM_COLOR_MODE_DISPLAY_P3>;
		oplus,output-mode = <MTK_PANEL_DSC_SINGLE_PORT>;
		oplus,panel-bpp = <10>;
		oplus,physical-width-um = <69331>;
		oplus,physical-height-um = <152352>;
		/* color */
		oplus,color-vivid-status;
		oplus,color-srgb-status;
		// oplus,color-softiris-status;
		// oplus,color-dual-panel-status;
		oplus,color-dual-brightness-status;
		oplus,color-oplus-calibrate-status;
		// oplus,color-samsung-status;
		oplus,color-loading-status;
		oplus,color-2nit-status;
		// oplus,color-nature-profession-status;
		/* ESD */
		oplus,cust-esd-check = <0>; // both check TE and reg
		oplus,esd-check-enable = <1>;
		oplus,esd_check_cmd = [
			0A
			0E
			AB
		];
		oplus,esd_check_count = [
			01
			01
			01
		];
		oplus,esd_check_value = [
			9C
			80
			00
		];
		oplus,esd_check_mask = [
			FF
			FF
			FF
		];
		/* MIPI error check config */
		/*
		 ** BIT(0): enable/disable check
		 ** BIT(1): enable/disable page switch
		 */
		oplus,mipi-err-check-config = <0x01>; // 0b0000'0111
		oplus,mipi-err-check-reg = [
			AB
		];
		oplus,mipi-err-check-value = [
			00 00
		];
		oplus,mipi-err-check-count = [
			02
		];
		/*  32-bit binary flag
		 ** Bit value identified how to match the return value of each register.
		 ** The value 0(default) means equal, and the value 1 means not equal.
		 */
		oplus,mipi-err-check-match-modes = <0x00000000>;
	};
};
